# cslr_psc register map
Vendor: Texas Instruments
Peripheral module from a debugger description file (folder TCI6484_C6457).
Registers are 32-bit, access not given, reset 0xA00 unless marked. A register's access mark holds for its fields unless they carry their own. Offsets are as the file gives them; lines under a group give offsets from that group; [hi:lo] are bit positions; {n}, {i} and the like mark numbered series; 'fields as' and 'values as' point back to an identical list; <NAME> marks a mode.

## PSC — Power and Sleep Controller
0x00 PID ro reset 0x44823A00 — Peripheral ID Register
  [31:0] PID — Peripheral ID used to differentiate different modules in the system
0x120 PTCMD reset 0x0 — Power Transtion Command Register
  [5:0] GO wo — Power Domain GO Transition Command
    1=SET (Writes of 1 sets corresponding PTSTAT.GOSTAT field, which causes PSC hardware to evaluate PDCTL.NEXT and MDCTL.NEXT)
0x128 PTSTAT reset 0x0 — Power Domain Transition Status
  [5:0] GOSTAT ro — Power domain transition status
    0=NO_PWRDMN_TRANS (No transitions in progress); 1=PWRDMN_TRANS_PROG (Transition in progress)
0x200 PDSTAT0 reset 0x301 — Power Domain Status Register
  [1:0] STATE — Power domain status
    0=OFF (Power Domain is in the OFF state.); 1=ON (Power Domain is in the ON state.)
{0x200+4i} PDSTAT{i} reset 0x300 (i=1..4) — Power Domain Status Register
  fields as PDSTAT0
0x300 PDCTL0 reset 0x1B001 — Power Domain Control Register
  [0] NEXT rw — Power domain next state
    0=OFF (Power Domain OFF.); 1=ON (Power Domain ON.)
{0x300+4i} PDCTL{i} reset 0x338000 (i=1..4) — Power Domain Control Register
  fields as PDCTL0
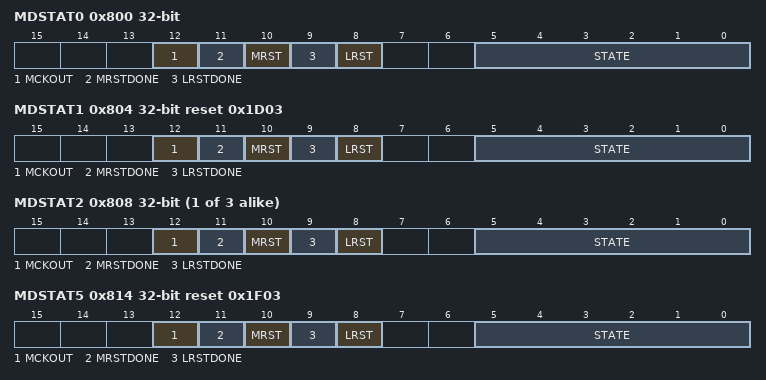
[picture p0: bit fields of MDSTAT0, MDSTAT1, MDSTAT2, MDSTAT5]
0x800 MDSTAT0 — Module Status Register
  [12] MCKOUT ro — Actual module output to module
    0=OFF; 1=ON
  [11] MRSTDONE ro — Module reset done. Software is responsible for checking that mode reset is done before accessing
    0=NO; 1=YES
  [10] MRST ro — Module reset actual status
    0=ASSERT; 1=DE_ASSERT
  [9] LRSTDONE ro — Local reset done. Software is responsible for checking that local reset is done before accessing this module
    0=NO; 1=YES
  [8] LRST ro — Module Local Reset status.
    0=ASSERT; 1=DE_ASSERT
  [5:0] STATE ro — These bits indicate the current module state
0x804 MDSTAT1 reset 0x1D03 — Module Status Register
  fields as MDSTAT0
{0x800+4i} MDSTAT{i} (i=2..4) — Module Status Register
  fields as MDSTAT0
0x814 MDSTAT5 reset 0x1F03 — Module Status Register
  fields as MDSTAT0
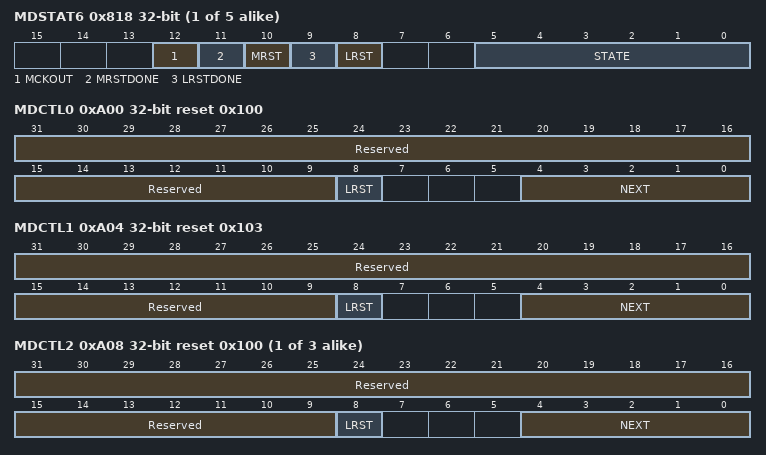
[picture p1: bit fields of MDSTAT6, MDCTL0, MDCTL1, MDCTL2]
{0x800+4i} MDSTAT{i} (i=6..10) — Module Status Register
  fields as MDSTAT0
0xA00 MDCTL0 reset 0x100 — Module Control Register
  [31:9] Reserved — (access N)
  [8] LRST rw — Module local reset control
    0=ASSERT (Assert local reset.); 1=DE_ASSERT (De-assert local reset.)
  [4:0] NEXT rw — Module Next State
0xA04 MDCTL1 reset 0x103 — Module Control Register
  fields as MDCTL0
{0xA00+4i} MDCTL{i} reset 0x100 (i=2..4) — Module Control Register
  fields as MDCTL0
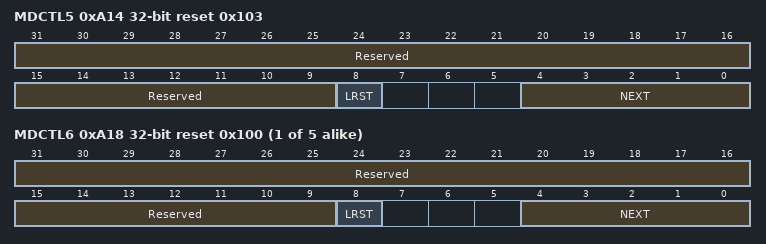
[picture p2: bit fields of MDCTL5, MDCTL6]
0xA14 MDCTL5 reset 0x103 — Module Control Register
  fields as MDCTL0
{0xA00+4i} MDCTL{i} reset 0x100 (i=6..10) — Module Control Register
  fields as MDCTL0
